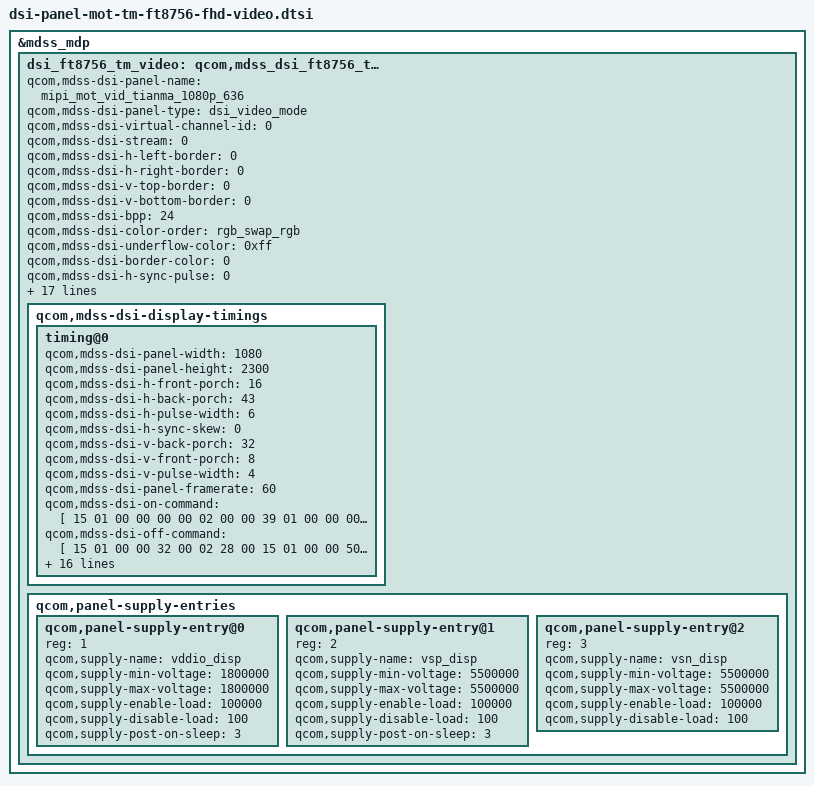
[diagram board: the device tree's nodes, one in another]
/* Copyright (c) 2018-2019, The Linux Foundation. All rights reserved.
 *
 * This program is free software; you can redistribute it and/or modify
 * it under the terms of the GNU General Public License version 2 and
 * only version 2 as published by the Free Software Foundation.
 *
 * This program is distributed in the hope that it will be useful,
 * but WITHOUT ANY WARRANTY; without even the implied warranty of
 * MERCHANTABILITY or FITNESS FOR A PARTICULAR PURPOSE.  See the
 * GNU General Public License for more details.
 */

&mdss_mdp {
	dsi_ft8756_tm_video: qcom,mdss_dsi_ft8756_tm_video {
		qcom,mdss-dsi-panel-name =
				"mipi_mot_vid_tianma_1080p_636";
		qcom,mdss-dsi-panel-type = "dsi_video_mode";

		qcom,mdss-dsi-virtual-channel-id = <0>;
		qcom,mdss-dsi-stream = <0>;
		qcom,mdss-dsi-h-left-border = <0>;
		qcom,mdss-dsi-h-right-border = <0>;
		qcom,mdss-dsi-v-top-border = <0>;
		qcom,mdss-dsi-v-bottom-border = <0>;
		qcom,mdss-dsi-bpp = <24>;
		qcom,mdss-dsi-color-order = "rgb_swap_rgb";
		qcom,mdss-dsi-underflow-color = <0xff>;
		qcom,mdss-dsi-border-color = <0>;
		qcom,mdss-dsi-h-sync-pulse = <0>;
		qcom,mdss-dsi-traffic-mode = "non_burst_sync_event";
		qcom,mdss-dsi-lane-map = "lane_map_0123";
		qcom,mdss-dsi-bllp-eof-power-mode;
		qcom,mdss-dsi-bllp-power-mode;
		qcom,mdss-dsi-tx-eot-append;
		qcom,mdss-dsi-lane-0-state;
		qcom,mdss-dsi-lane-1-state;
		qcom,mdss-dsi-lane-2-state;
		qcom,mdss-dsi-lane-3-state;
		qcom,mdss-dsi-dma-trigger = "trigger_sw";
		qcom,mdss-dsi-mdp-trigger = "none";
		qcom,mdss-dsi-lp11-init;
		//qcom,mdss-dsi-bl-pmic-control-type = "bl_ctrl_dcs";
		qcom,mdss-dsi-bl-min-level = <1>;
		qcom,mdss-dsi-bl-max-level = <255>;
		qcom,mdss-dsi-reset-assert-time = <5>;
		qcom,mdss-dsi-reset-sequence = <1 4>, <0 1>, <1 11>;
		/*
		qcom,mdss-pan-physical-width-dimension = <65>;
		qcom,mdss-pan-physical-height-dimension = <129>;
		*/
		qcom,mdss-dsi-display-timings {
			timing@0 {
				qcom,mdss-dsi-panel-width = <1080>;
				qcom,mdss-dsi-panel-height = <2300>;
				qcom,mdss-dsi-h-front-porch = <16>;
				qcom,mdss-dsi-h-back-porch = <43>;
				qcom,mdss-dsi-h-pulse-width = <6>;
				qcom,mdss-dsi-h-sync-skew = <0>;
				qcom,mdss-dsi-v-back-porch = <32>;
				qcom,mdss-dsi-v-front-porch = <8>;
				qcom,mdss-dsi-v-pulse-width = <4>;
				qcom,mdss-dsi-panel-framerate = <60>;
				qcom,mdss-dsi-on-command =
				[
					15 01 00 00 00 00 02 00 00
					39 01 00 00 00 00 04 FF 87 56 01
					15 01 00 00 00 00 02 00 80
					39 01 00 00 00 00 03 FF 87 56//cmd2 enable
					15 01 00 00 00 00 02 00 80
					39 01 00 00 00 00 07 C0 00 92 00 08 00 24
					15 01 00 00 00 00 02 00 90
					39 01 00 00 00 00 07 C0 00 92 00 08 00 24
					15 01 00 00 00 00 02 00 B0
					39 01 00 00 00 00 06 C0 00 92 00 08 24
					15 01 00 00 00 00 02 00 C1
					39 01 00 00 00 00 09 C0 00 D9 00 A5 00 91 00 F8
					15 01 00 00 00 00 02 00 D7
					39 01 00 00 00 00 07 C0 00 91 00 08 00 24
					15 01 00 00 00 00 02 00 90
					39 01 00 00 00 00 10 CE 00 8E 0C DF 00 8E 80 09 13 00 04 00 1E 1F 16
					15 01 00 00 00 00 02 00 F1
					39 01 00 00 00 00 0A CE 12 09 0C 01 1B 01 1C 01 36
					15 01 00 00 00 00 02 00 B0
					39 01 00 00 00 00 05 CF 00 00 BF C3
					15 01 00 00 00 00 02 00 A0
					39 01 00 00 00 00 07 C0 00 92 00 08 00 24
					15 01 00 00 00 00 02 00 00
					39 01 00 00 00 00 04 FF FF FF FF
					15 01 00 00 00 00 02 00 80
					39 01 00 00 00 00 03 FF FF FF//cmd2 enable
					15 01 00 00 00 00 02 51 A3
					15 01 00 00 00 00 02 53 24
					15 01 00 00 00 00 02 55 01
					15 01 00 00 60 00 02 11 00
					15 01 00 00 00 00 02 29 00
				];
				qcom,mdss-dsi-off-command = [
					15 01 00 00 32 00 02 28 00
					15 01 00 00 50 00 02 10 00
					15 01 00 00 00 00 02 00 00
					39 01 00 00 00 00 04 FF 87 56 01
					15 01 00 00 00 00 02 00 80
					39 01 00 00 00 00 03 FF 87 56//cmd2 enable
					39 01 00 00 00 00 02 00 00
					39 01 00 00 00 00 05 F7 5A A5 95 27
				];
				qcom,mdss-dsi-t-clk-post = <0x0e>;
				qcom,mdss-dsi-t-clk-pre = <0x33>;
				qcom,mdss-dsi-on-command-state = "dsi_lp_mode";
				qcom,mdss-dsi-off-command-state = "dsi_hs_mode";

				qcom,mdss-dsi-cabc-mv-command = [15 01 00 00 00 00 02 55 03];
				qcom,mdss-dsi-cabc-mv-command-state =  "dsi_lp_mode";
				qcom,mdss-dsi-cabc-ui-command = [15 01 00 00 00 00 02 55 01];
				qcom,mdss-dsi-cabc-ui-command-state =  "dsi_lp_mode";
				qcom,mdss-dsi-cabc-dis-command = [15 01 00 00 00 00 02 55 00];
				qcom,mdss-dsi-cabc-dis-command-state =  "dsi_lp_mode";
			};
		};

		qcom,panel-supply-entries {
			#address-cells = <1>;
			#size-cells = <0>;

			qcom,panel-supply-entry@0 {
				reg = <1>;
				qcom,supply-name = "vddio_disp";
				qcom,supply-min-voltage = <1800000>;
				qcom,supply-max-voltage = <1800000>;
				qcom,supply-enable-load = <100000>;
				qcom,supply-disable-load = <100>;
				qcom,supply-post-on-sleep = <3>;
			};

			qcom,panel-supply-entry@1 {
				reg = <2>;
				qcom,supply-name = "vsp_disp";
				qcom,supply-min-voltage = <5500000>;
				qcom,supply-max-voltage = <5500000>;
				qcom,supply-enable-load = <100000>;
				qcom,supply-disable-load = <100>;
				qcom,supply-post-on-sleep = <3>;
			};

			qcom,panel-supply-entry@2 {
				reg = <3>;
				qcom,supply-name = "vsn_disp";
				qcom,supply-min-voltage = <5500000>;
				qcom,supply-max-voltage = <5500000>;
				qcom,supply-enable-load = <100000>;
				qcom,supply-disable-load = <100>;
			};
		};

	};
};
